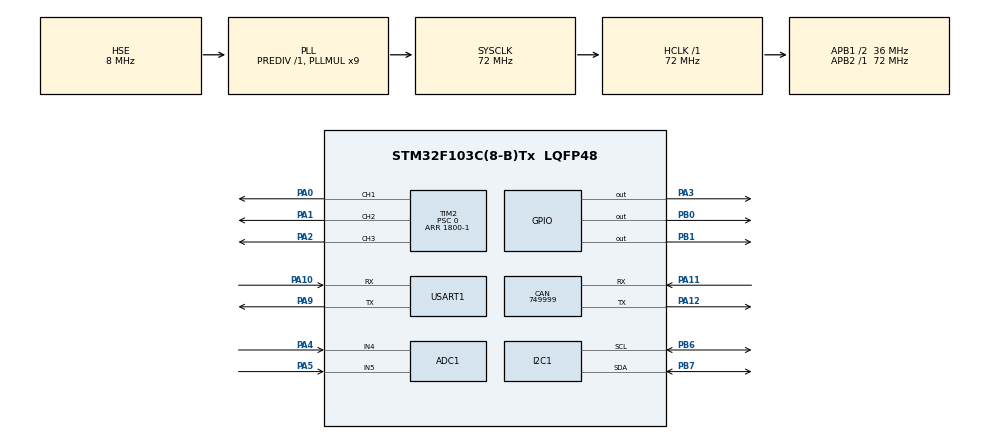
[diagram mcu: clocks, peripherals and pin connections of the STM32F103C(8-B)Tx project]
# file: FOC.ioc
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ADC1.Channel-2\#ChannelInjectedConversion=ADC_CHANNEL_4
ADC1.Channel-3\#ChannelInjectedConversion=ADC_CHANNEL_5
ADC1.EnableInjectedConversion=ENABLE
ADC1.EnableRegularConversion=DISABLE
ADC1.ExternalTrigInjecConv=ADC_EXTERNALTRIGINJECCONV_T2_TRGO
ADC1.InjNumberOfConversion=2
ADC1.InjectedOffset-2\#ChannelInjectedConversion=0
ADC1.InjectedOffset-3\#ChannelInjectedConversion=0
ADC1.InjectedRank-2\#ChannelInjectedConversion=1
ADC1.InjectedRank-3\#ChannelInjectedConversion=2
ADC1.SamplingTime-2\#ChannelInjectedConversion=ADC_SAMPLETIME_1CYCLE_5
ADC1.SamplingTime-3\#ChannelInjectedConversion=ADC_SAMPLETIME_1CYCLE_5
ADC1.master=1
CAN.CalculateBaudRate=749999
CAN.CalculateTimeBit=1333
CAN.CalculateTimeQuantum=444.44444444444446
Dma.Request0=USART1_TX
Dma.USART1_TX.0.Direction=DMA_MEMORY_TO_PERIPH
Dma.USART1_TX.0.Instance=DMA1_Channel4
Dma.USART1_TX.0.MemDataAlignment=DMA_MDATAALIGN_BYTE
Dma.USART1_TX.0.MemInc=DMA_MINC_ENABLE
Dma.USART1_TX.0.Mode=DMA_NORMAL
Dma.USART1_TX.0.PeriphDataAlignment=DMA_PDATAALIGN_BYTE
Dma.USART1_TX.0.PeriphInc=DMA_PINC_DISABLE
Dma.USART1_TX.0.Priority=DMA_PRIORITY_LOW
Mcu.Family=STM32F1
Mcu.Name=STM32F103C(8-B)Tx
Mcu.Package=LQFP48
NVIC.ADC1_2_IRQn=true\:0\:0\:false\:false\:true\:true\:true\:true
NVIC.DMA1_Channel4_IRQn=true\:0\:0\:false\:false\:true\:true\:true\:true
NVIC.PriorityGroup=NVIC_PRIORITYGROUP_4
NVIC.TIM3_IRQn=true\:1\:0\:true\:false\:true\:true\:true\:true
NVIC.USART1_IRQn=true\:0\:0\:false\:false\:true\:true\:true\:true
PA0-WKUP.Signal=S_TIM2_CH1_ETR
PA1.Signal=S_TIM2_CH2
PA10.Mode=Asynchronous
PA10.Signal=USART1_RX
PA11.Mode=CAN_Activate
PA11.Signal=CAN_RX
PA12.Mode=CAN_Activate
PA12.Signal=CAN_TX
PA13.Mode=Serial_Wire
PA13.Signal=SYS_JTMS-SWDIO
PA14.Mode=Serial_Wire
PA14.Signal=SYS_JTCK-SWCLK
PA2.Signal=S_TIM2_CH3
PA3.Signal=GPIO_Output
PA4.Signal=ADCx_IN4
PA5.Signal=ADCx_IN5
PA9.Mode=Asynchronous
PA9.Signal=USART1_TX
PB0.Signal=GPIO_Output
PB1.Signal=GPIO_Output
PB6.Mode=I2C
PB6.Signal=I2C1_SCL
PB7.Mode=I2C
PB7.Signal=I2C1_SDA
PD0-OSC_IN.Mode=HSE-External-Oscillator
PD0-OSC_IN.Signal=RCC_OSC_IN
PD1-OSC_OUT.Mode=HSE-External-Oscillator
PD1-OSC_OUT.Signal=RCC_OSC_OUT
ProjectManager.HeapSize=0x200
ProjectManager.StackSize=0x400
ProjectManager.TargetToolchain=MDK-ARM V5.32
RCC.ADCPresc=RCC_ADCPCLK2_DIV6
RCC.AHBFreq_Value=72000000
RCC.APB1CLKDivider=RCC_HCLK_DIV2
RCC.APB1Freq_Value=36000000
RCC.APB1TimFreq_Value=72000000
RCC.APB2Freq_Value=72000000
RCC.APB2TimFreq_Value=72000000
RCC.HCLKFreq_Value=72000000
RCC.PLLMUL=RCC_PLL_MUL9
RCC.PLLSourceVirtual=RCC_PLLSOURCE_HSE
RCC.SYSCLKFreq_VALUE=72000000
RCC.SYSCLKSource=RCC_SYSCLKSOURCE_PLLCLK
RCC.USBFreq_Value=72000000
SH.ADCx_IN4.0=ADC1_IN4,IN4
SH.ADCx_IN5.0=ADC1_IN5,IN5
SH.S_TIM2_CH1_ETR.0=TIM2_CH1,PWM Generation1 CH1
SH.S_TIM2_CH2.0=TIM2_CH2,PWM Generation2 CH2
SH.S_TIM2_CH3.0=TIM2_CH3,PWM Generation3 CH3
TIM2.AutoReloadPreload=TIM_AUTORELOAD_PRELOAD_ENABLE
TIM2.Channel-PWM\ Generation1\ CH1=TIM_CHANNEL_1
TIM2.Channel-PWM\ Generation2\ CH2=TIM_CHANNEL_2
TIM2.Channel-PWM\ Generation3\ CH3=TIM_CHANNEL_3
TIM2.Channel-PWM\ Generation4\ No\ Output=TIM_CHANNEL_4
TIM2.CounterMode=TIM_COUNTERMODE_CENTERALIGNED1
TIM2.Period=1800-1
TIM2.Prescaler=0
TIM2.Pulse-PWM\ Generation1\ CH1=900-1
TIM2.Pulse-PWM\ Generation2\ CH2=900-1
TIM2.Pulse-PWM\ Generation3\ CH3=900-1
TIM2.Pulse-PWM\ Generation4\ No\ Output=1795-1
TIM2.TIM_MasterOutputTrigger=TIM_TRGO_OC4REF
TIM2.TIM_MasterSlaveMode=TIM_MASTERSLAVEMODE_ENABLE
TIM3.AutoReloadPreload=TIM_AUTORELOAD_PRELOAD_ENABLE
TIM3.CounterMode=TIM_COUNTERMODE_CENTERALIGNED2
TIM3.Period=1800-1
TIM3.TIM_MasterSlaveMode=TIM_MASTERSLAVEMODE_ENABLE
USART1.VirtualMode=VM_ASYNC
VP_TIM2_VS_ClockSourceINT.Mode=Internal
VP_TIM2_VS_no_output4.Mode=PWM Generation4 No Output
VP_TIM3_VS_ClockSourceINT.Mode=Internal
board=custom

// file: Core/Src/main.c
/* USER CODE BEGIN Header */
/**
  ******************************************************************************
  * @file           : main.c
  * @brief          : Main program body
  ******************************************************************************
  * @attention
  *
  * Copyright (c) 2026 STMicroelectronics.
  * All rights reserved.
  *
  * This software is licensed under terms that can be found in the LICENSE file
  * in the root directory of this software component.
  * If no LICENSE file comes with this software, it is provided AS-IS.
  *
  ******************************************************************************
  */
/* USER CODE END Header */
#include "main.h"
#include "adc.h"
#include "can.h"
#include "dma.h"
#include "i2c.h"
#include "tim.h"
#include "usart.h"
#include "gpio.h"

/* USER CODE BEGIN Includes */
#include "app_comm.h"
#include "app_motor.h"
#include "foc.h"
/* USER CODE END Includes */

void SystemClock_Config(void);

int main(void)
{

  /* MCU Configuration--------------------------------------------------------*/

  /* Reset of all peripherals, Initializes the Flash interface and the Systick. */
  HAL_Init();

  /* Configure the system clock */
  SystemClock_Config();

  /* Initialize all configured peripherals */
  MX_GPIO_Init();
  MX_DMA_Init();
  MX_I2C1_Init();
  MX_USART1_UART_Init();
  MX_ADC1_Init();
  MX_CAN_Init();
  MX_TIM2_Init();
  MX_TIM3_Init();
  /* USER CODE BEGIN 2 */
  Foc_Init(1, &foc_hal);

  HAL_Delay(50); // 延时防止还没有初始化完就进入中断
  Foc_Set_Speed(1, 1100.0f);
  // uint8_t uart_test_data[] = {'2'};
  // float angle = 1.0f;
  /* USER CODE END 2 */

  /* Infinite loop */
  /* USER CODE BEGIN WHILE */
  while (1)
  {
    // if(AS5600_GetMechanicalAngle(&angle) == HAL_OK)
    // {
    //   uint8_t len = sprintf((char*)uart_test_data, "%f\n", angle);
    //   app_uart_send(uart_test_data, len);
    // }
    app_foc_mainloop();
    app_debug_print();
    // HAL_GPIO_WritePin(GPIOB, GPIO_PIN_0, GPIO_PIN_SET);

    // if(AS5600_IsConnected())
    //   app_uart_send("1", 2);
    // else
    //   app_uart_send("2", 2);
    /* USER CODE END WHILE */

  }
}

void SystemClock_Config(void)
{
  RCC_OscInitTypeDef RCC_OscInitStruct = {0};
  RCC_ClkInitTypeDef RCC_ClkInitStruct = {0};
  RCC_PeriphCLKInitTypeDef PeriphClkInit = {0};

  /** Initializes the RCC Oscillators according to the specified parameters
  * in the RCC_OscInitTypeDef structure.
  */
  RCC_OscInitStruct.OscillatorType = RCC_OSCILLATORTYPE_HSE;
  RCC_OscInitStruct.HSEState = RCC_HSE_ON;
  RCC_OscInitStruct.HSEPredivValue = RCC_HSE_PREDIV_DIV1;
  RCC_OscInitStruct.HSIState = RCC_HSI_ON;
  RCC_OscInitStruct.PLL.PLLState = RCC_PLL_ON;
  RCC_OscInitStruct.PLL.PLLSource = RCC_PLLSOURCE_HSE;
  RCC_OscInitStruct.PLL.PLLMUL = RCC_PLL_MUL9;
  if (HAL_RCC_OscConfig(&RCC_OscInitStruct) != HAL_OK)
  {
    Error_Handler();
  }

  /** Initializes the CPU, AHB and APB buses clocks
  */
  RCC_ClkInitStruct.ClockType = RCC_CLOCKTYPE_HCLK|RCC_CLOCKTYPE_SYSCLK
                              |RCC_CLOCKTYPE_PCLK1|RCC_CLOCKTYPE_PCLK2;
  RCC_ClkInitStruct.SYSCLKSource = RCC_SYSCLKSOURCE_PLLCLK;
  RCC_ClkInitStruct.AHBCLKDivider = RCC_SYSCLK_DIV1;
  RCC_ClkInitStruct.APB1CLKDivider = RCC_HCLK_DIV2;
  RCC_ClkInitStruct.APB2CLKDivider = RCC_HCLK_DIV1;

  if (HAL_RCC_ClockConfig(&RCC_ClkInitStruct, FLASH_LATENCY_2) != HAL_OK)
  {
    Error_Handler();
  }
  PeriphClkInit.PeriphClockSelection = RCC_PERIPHCLK_ADC;
  PeriphClkInit.AdcClockSelection = RCC_ADCPCLK2_DIV6;
  if (HAL_RCCEx_PeriphCLKConfig(&PeriphClkInit) != HAL_OK)
  {
    Error_Handler();
  }
}

void Error_Handler(void)
{
  __disable_irq();
  while (1)
  {
  }
}
